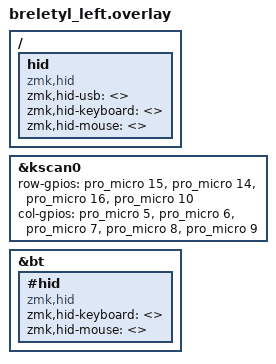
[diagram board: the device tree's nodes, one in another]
#include "breletyl.dtsi" // The shared dtsi file is included in the overlay

// Label of the kscan node in the dtsi
&kscan0 {

    row-gpios
        = <&pro_micro 15 (GPIO_ACTIVE_HIGH | GPIO_PULL_DOWN)>
        , <&pro_micro 14 (GPIO_ACTIVE_HIGH | GPIO_PULL_DOWN)>
        , <&pro_micro 16 (GPIO_ACTIVE_HIGH | GPIO_PULL_DOWN)>
        , <&pro_micro 10 (GPIO_ACTIVE_HIGH | GPIO_PULL_DOWN)>
        ;

    col-gpios
        = <&pro_micro 5 GPIO_ACTIVE_HIGH>
        , <&pro_micro 6 GPIO_ACTIVE_HIGH>
        , <&pro_micro 7 GPIO_ACTIVE_HIGH>
        , <&pro_micro 8 GPIO_ACTIVE_HIGH>
        , <&pro_micro 9 GPIO_ACTIVE_HIGH>
        ;
};

// USB HID configuration (attached at root)
 / {
    hid {
        compatible = "zmk,hid";
        zmk,hid-usb = <>;
        zmk,hid-keyboard = <>;
        zmk,hid-mouse = <>;
    };
};

// Bluetooth HID configuration (attached to minimal BT node)
&bt {
    #hid {
        compatible = "zmk,hid";
        zmk,hid-keyboard = <>;
        zmk,hid-mouse = <>;
    };
};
